VERSION ""

NS_ :

BS_:

BU_: VCU

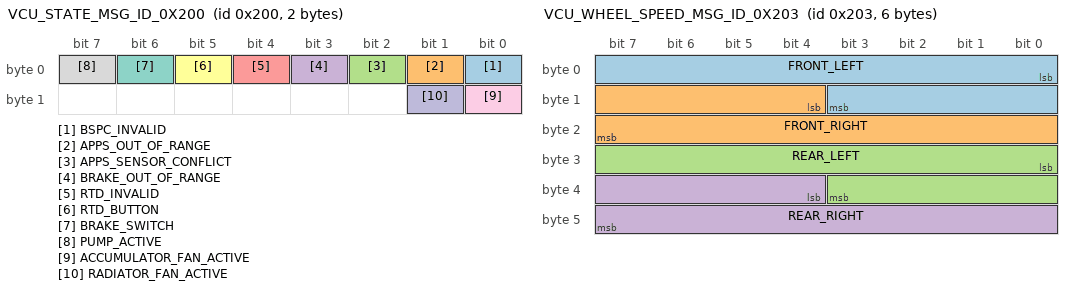
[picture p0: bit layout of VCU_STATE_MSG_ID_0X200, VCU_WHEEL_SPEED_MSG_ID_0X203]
BO_ 512 VCU_STATE_MSG_ID_0X200: 2 VCU
 SG_ BSPC_INVALID : 0|1@1+ (1,0) [0|1] "bool" Vector__XXX
 SG_ APPS_OUT_OF_RANGE : 1|1@1+ (1,0) [0|1] "bool" Vector__XXX
 SG_ APPS_SENSOR_CONFLICT : 2|1@1+ (1,0) [0|1] "bool" Vector__XXX
 SG_ BRAKE_OUT_OF_RANGE : 3|1@1+ (1,0) [0|1] "bool" Vector__XXX
 SG_ RTD_INVALID : 4|1@1+ (1,0) [0|1] "bool" Vector__XXX
 SG_ RTD_BUTTON : 5|1@1+ (1,0) [0|1] "bool" Vector__XXX
 SG_ BRAKE_SWITCH : 6|1@1+ (1,0) [0|1] "bool" Vector__XXX
 SG_ PUMP_ACTIVE : 7|1@1+ (1,0) [0|1] "bool" Vector__XXX
 SG_ ACCUMULATOR_FAN_ACTIVE : 8|1@1+ (1,0) [0|1] "bool" Vector__XXX
 SG_ RADIATOR_FAN_ACTIVE : 9|1@1+ (1,0) [0|1] "bool" Vector__XXX

BO_ 513 VCU_SENSORS_MSG_ID_0X201: 4 VCU
 SG_ BRAKE_PRESSURE : 0|16@1+ (0.1,0) [0|2000] "PSI" Vector__XXX
 SG_ ACCELERATOR_POSITION : 16|16@1+ (0.1,0) [0|100] "%" Vector__XXX

BO_ 514 VCU_COOLANT_PRESSURE_MSG_ID_0X202: 2 VCU
 SG_ COOLANT_PRESSURE : 0|8@1- (1,0) [-127|128] "PSI" Vector__XXX
 SG_ COOLANT_PRESSURE_2 : 8|8@1- (1,0) [-127|128] "PSI" Vector__XXX

BO_ 515 VCU_WHEEL_SPEED_MSG_ID_0X203: 6 VCU
 SG_ FRONT_LEFT : 0|12@1+ (1,0) [0|1] "rpm" Vector__XXX
 SG_ FRONT_RIGHT : 12|12@1- (1,0) [0|1] "rpm" Vector__XXX
 SG_ REAR_LEFT : 24|12@1- (1,0) [0|1] "rpm" Vector__XXX
 SG_ REAR_RIGHT : 36|12@1- (1,0) [0|1] "rpm" Vector__XXX

BA_DEF_  "BusType" STRING ;
BA_DEF_DEF_  "BusType" "CAN";
